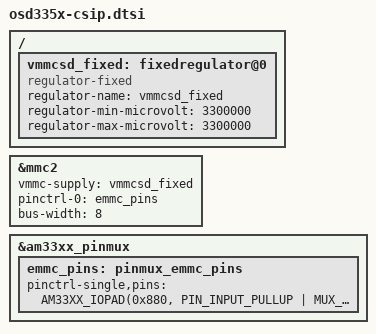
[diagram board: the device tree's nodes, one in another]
/*
 * Device Tree Source for OSD335x SoC
 *
 * Copyright (C) 2017 Octavo Systems LLC - http://www.octavosystems.com/
 *
 * This file is licensed under the terms of the GNU General Public License
 * version 2.  This program is licensed "as is" without any warranty of any
 * kind, whether express or implied.
 */


#include "osd335x-sm.dtsi"

/ {
    vmmcsd_fixed: fixedregulator@0 {
 	    compatible = "regulator-fixed";
 	    regulator-name = "vmmcsd_fixed";
 	    regulator-min-microvolt = <3300000>;
 	    regulator-max-microvolt = <3300000>;
     };
};

&mmc2 {
	vmmc-supply = <&vmmcsd_fixed>;
	pinctrl-names = "default";
	pinctrl-0 = <&emmc_pins>;
	bus-width = <8>;
	status = "okay";
};

&am33xx_pinmux {
    emmc_pins: pinmux_emmc_pins {
        pinctrl-single,pins = <
        AM33XX_IOPAD(0x880, PIN_INPUT_PULLUP | MUX_MODE2) /* gpmc_csn1.mmc1_clk */
        AM33XX_IOPAD(0x884, PIN_INPUT_PULLUP | MUX_MODE2) /* gpmc_csn2.mmc1_cmd */
        AM33XX_IOPAD(0x800, PIN_INPUT_PULLUP | MUX_MODE1) /* gpmc_ad0.mmc1_dat0 */
        AM33XX_IOPAD(0x804, PIN_INPUT_PULLUP | MUX_MODE1) /* gpmc_ad1.mmc1_dat1 */
        AM33XX_IOPAD(0x808, PIN_INPUT_PULLUP | MUX_MODE1) /* gpmc_ad2.mmc1_dat2 */
        AM33XX_IOPAD(0x80c, PIN_INPUT_PULLUP | MUX_MODE1) /* gpmc_ad3.mmc1_dat3 */
        AM33XX_IOPAD(0x810, PIN_INPUT_PULLUP | MUX_MODE1) /* gpmc_ad4.mmc1_dat4 */
        AM33XX_IOPAD(0x814, PIN_INPUT_PULLUP | MUX_MODE1) /* gpmc_ad5.mmc1_dat5 */
        AM33XX_IOPAD(0x818, PIN_INPUT_PULLUP | MUX_MODE1) /* gpmc_ad6.mmc1_dat6 */
        AM33XX_IOPAD(0x81c, PIN_INPUT_PULLUP | MUX_MODE1) /* gpmc_ad7.mmc1_dat7 */
        >;
    };
};
